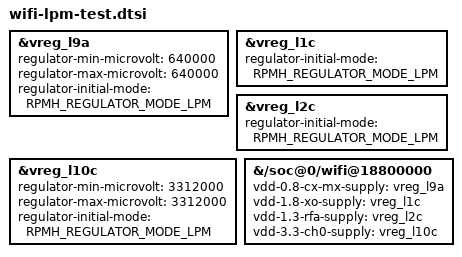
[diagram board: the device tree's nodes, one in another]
/* TEST wifi-lpm: Android-like WCN power (stock MIUI trace): direct rails, LPM, no PMU, no ch1 */
/ {
	/delete-node/ wcn3990-pmu;
};

&vreg_l9a {
	regulator-min-microvolt = <640000>;
	regulator-max-microvolt = <640000>;
	regulator-initial-mode = <RPMH_REGULATOR_MODE_LPM>;
};

&vreg_l1c {
	regulator-initial-mode = <RPMH_REGULATOR_MODE_LPM>;
};

&vreg_l2c {
	regulator-initial-mode = <RPMH_REGULATOR_MODE_LPM>;
};

&vreg_l10c {
	regulator-min-microvolt = <3312000>;
	regulator-max-microvolt = <3312000>;
	regulator-initial-mode = <RPMH_REGULATOR_MODE_LPM>;
};

&{/soc@0/wifi@18800000} {
	vdd-0.8-cx-mx-supply = <&vreg_l9a>;
	vdd-1.8-xo-supply = <&vreg_l1c>;
	vdd-1.3-rfa-supply = <&vreg_l2c>;
	vdd-3.3-ch0-supply = <&vreg_l10c>;
	/delete-property/ vdd-3.3-ch1-supply;
	status = "okay";
};
